VERSION "GT86 bus: what the GT86-ISF gateway sends (generated by tools/generate.py)"

NS_ :

BS_:

BU_: GATEWAY ADU GT86

BO_ 208 GT86_GSensor: 8 GATEWAY

BO_ 209 GT86_VehicleSpeed: 8 GATEWAY
 SG_ GT86_VehicleSpeed : 0|16@1+ (0.0565,0) [0|3702.73] "km/h" GT86

BO_ 210 GT86_Unknown_D2: 8 GATEWAY

BO_ 211 GT86_LightStatus: 8 GATEWAY

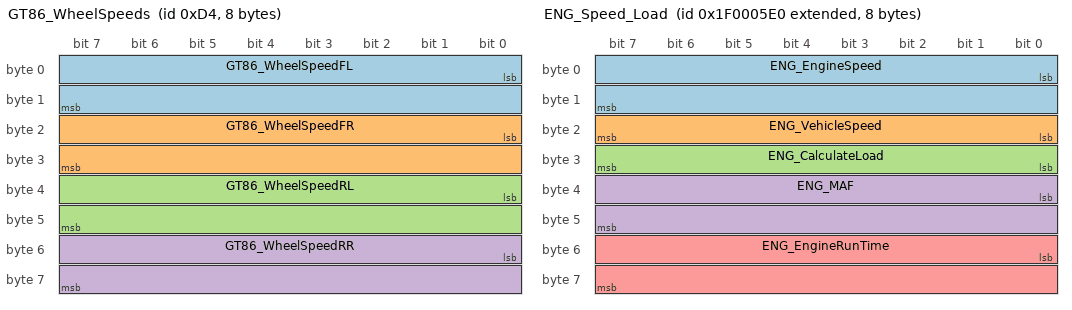
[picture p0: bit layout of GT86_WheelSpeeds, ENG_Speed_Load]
BO_ 212 GT86_WheelSpeeds: 8 GATEWAY
 SG_ GT86_WheelSpeedFL : 0|16@1+ (0.0565,0) [0|3702.73] "km/h" GT86
 SG_ GT86_WheelSpeedFR : 16|16@1+ (0.0565,0) [0|3702.73] "km/h" GT86
 SG_ GT86_WheelSpeedRL : 32|16@1+ (0.0565,0) [0|3702.73] "km/h" GT86
 SG_ GT86_WheelSpeedRR : 48|16@1+ (0.0565,0) [0|3702.73] "km/h" GT86

BO_ 320 GT86_EngineData1: 8 GATEWAY

BO_ 321 GT86_EngineData2: 8 GATEWAY
 SG_ GT86_EngineRPM : 32|14@1+ (1,0) [0|16383] "rpm" GT86

BO_ 322 GT86_EngineMisc: 8 GATEWAY

BO_ 324 GT86_BrakeData1: 8 GATEWAY

BO_ 864 GT86_Temperatures: 8 GATEWAY
 SG_ GT86_EngineOilTemperature : 16|8@1+ (1,-40) [-40|215] "°C" GT86
 SG_ GT86_CoolantTemperature : 24|8@1+ (1,-40) [-40|215] "°C" GT86

BO_ 865 GT86_GearData2: 8 GATEWAY

BO_ 880 GT86_SteeringTorque2: 8 GATEWAY

BO_ 1224 GT86_Unknown_4C8: 8 GATEWAY

BO_ 1953 GT86_ClusterDiagRequest: 8 GATEWAY

BO_ 1961 GT86_ClusterDiagResponse: 8 GATEWAY

BO_ 2667578848 ENG_Speed_Load: 8 GATEWAY
 SG_ ENG_EngineSpeed : 0|16@1+ (0.25,0) [0|16383.8] "rpm" ADU
 SG_ ENG_VehicleSpeed : 16|8@1+ (1,0) [0|255] "km/h" ADU
 SG_ ENG_CalculateLoad : 24|8@1+ (0.39215686274509803,0) [0|100] "%" ADU
 SG_ ENG_MAF : 32|16@1+ (0.01,0) [0|655.35] "g/s" ADU
 SG_ ENG_EngineRunTime : 48|16@1+ (1,0) [0|65535] "s" ADU

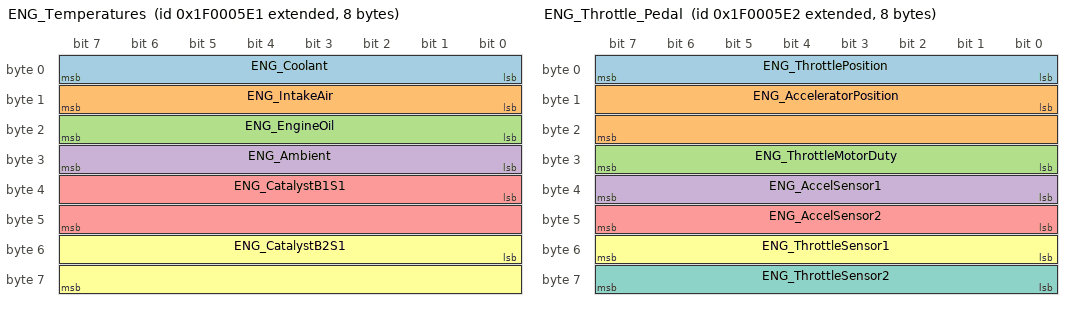
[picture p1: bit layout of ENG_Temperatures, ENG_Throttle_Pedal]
BO_ 2667578849 ENG_Temperatures: 8 GATEWAY
 SG_ ENG_Coolant : 0|8@1+ (1,-40) [-40|215] "°C" ADU
 SG_ ENG_IntakeAir : 8|8@1+ (1,-40) [-40|215] "°C" ADU
 SG_ ENG_EngineOil : 16|8@1+ (1,-40) [-40|215] "°C" ADU
 SG_ ENG_Ambient : 24|8@1+ (1,-40) [-40|215] "°C" ADU
 SG_ ENG_CatalystB1S1 : 32|16@1+ (0.1,-40) [-40|6513.5] "°C" ADU
 SG_ ENG_CatalystB2S1 : 48|16@1+ (0.1,-40) [-40|6513.5] "°C" ADU

BO_ 2667578850 ENG_Throttle_Pedal: 8 GATEWAY
 SG_ ENG_ThrottlePosition : 0|8@1+ (0.39215686274509803,0) [0|100] "%" ADU
 SG_ ENG_AcceleratorPosition : 8|16@1+ (0.006103515625,0) [0|399.994] "%" ADU
 SG_ ENG_ThrottleMotorDuty : 24|8@1+ (0.39215686274509803,0) [0|100] "%" ADU
 SG_ ENG_AccelSensor1 : 32|8@1+ (0.39215686274509803,0) [0|100] "%" ADU
 SG_ ENG_AccelSensor2 : 40|8@1+ (0.39215686274509803,0) [0|100] "%" ADU
 SG_ ENG_ThrottleSensor1 : 48|8@1+ (0.39215686274509803,0) [0|100] "%" ADU
 SG_ ENG_ThrottleSensor2 : 56|8@1+ (0.39215686274509803,0) [0|100] "%" ADU

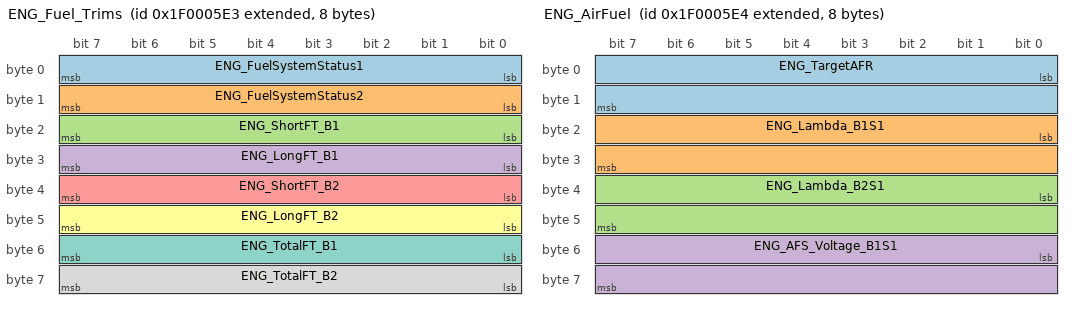
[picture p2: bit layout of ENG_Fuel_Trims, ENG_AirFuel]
BO_ 2667578851 ENG_Fuel_Trims: 8 GATEWAY
 SG_ ENG_FuelSystemStatus1 : 0|8@1+ (1,0) [0|255] "" ADU
 SG_ ENG_FuelSystemStatus2 : 8|8@1+ (1,0) [0|255] "" ADU
 SG_ ENG_ShortFT_B1 : 16|8@1+ (0.78125,-100) [-100|99.2188] "%" ADU
 SG_ ENG_LongFT_B1 : 24|8@1+ (0.78125,-100) [-100|99.2188] "%" ADU
 SG_ ENG_ShortFT_B2 : 32|8@1+ (0.78125,-100) [-100|99.2188] "%" ADU
 SG_ ENG_LongFT_B2 : 40|8@1+ (0.78125,-100) [-100|99.2188] "%" ADU
 SG_ ENG_TotalFT_B1 : 48|8@1+ (0.00390625,-0.5) [-0.5|0.496094] "" ADU
 SG_ ENG_TotalFT_B2 : 56|8@1+ (0.00390625,-0.5) [-0.5|0.496094] "" ADU

BO_ 2667578852 ENG_AirFuel: 8 GATEWAY
 SG_ ENG_TargetAFR : 0|16@1+ (3.05e-05,0) [0|1.99882] "" ADU
 SG_ ENG_Lambda_B1S1 : 16|16@1+ (3.05e-05,0) [0|1.99882] "" ADU
 SG_ ENG_Lambda_B2S1 : 32|16@1+ (3.05e-05,0) [0|1.99882] "" ADU
 SG_ ENG_AFS_Voltage_B1S1 : 48|16@1+ (0.000122,0) [0|7.99527] "V" ADU

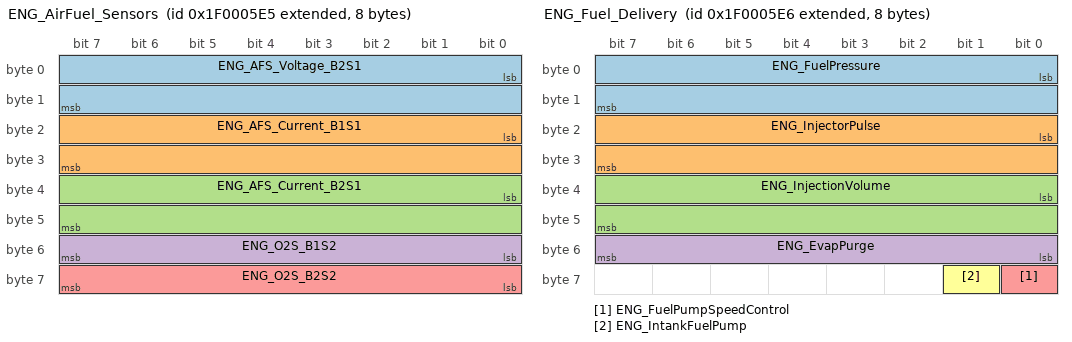
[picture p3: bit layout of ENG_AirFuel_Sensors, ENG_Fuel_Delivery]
BO_ 2667578853 ENG_AirFuel_Sensors: 8 GATEWAY
 SG_ ENG_AFS_Voltage_B2S1 : 0|16@1+ (0.000122,0) [0|7.99527] "V" ADU
 SG_ ENG_AFS_Current_B1S1 : 16|16@1+ (0.00390625,-128) [-128|127.996] "mA" ADU
 SG_ ENG_AFS_Current_B2S1 : 32|16@1+ (0.00390625,-128) [-128|127.996] "mA" ADU
 SG_ ENG_O2S_B1S2 : 48|8@1+ (0.005,0) [0|1.275] "V" ADU
 SG_ ENG_O2S_B2S2 : 56|8@1+ (0.005,0) [0|1.275] "V" ADU

BO_ 2667578854 ENG_Fuel_Delivery: 8 GATEWAY
 SG_ ENG_FuelPressure : 0|16@1+ (10,0) [0|655350] "kPa" ADU
 SG_ ENG_InjectorPulse : 16|16@1+ (1,0) [0|65535] "us" ADU
 SG_ ENG_InjectionVolume : 32|16@1+ (3.125e-05,0) [0|2.04797] "cm^3" ADU
 SG_ ENG_EvapPurge : 48|8@1+ (0.39215686274509803,0) [0|100] "%" ADU
 SG_ ENG_FuelPumpSpeedControl : 56|1@1+ (1,0) [0|1] "" ADU
 SG_ ENG_IntankFuelPump : 57|1@1+ (1,0) [0|1] "" ADU

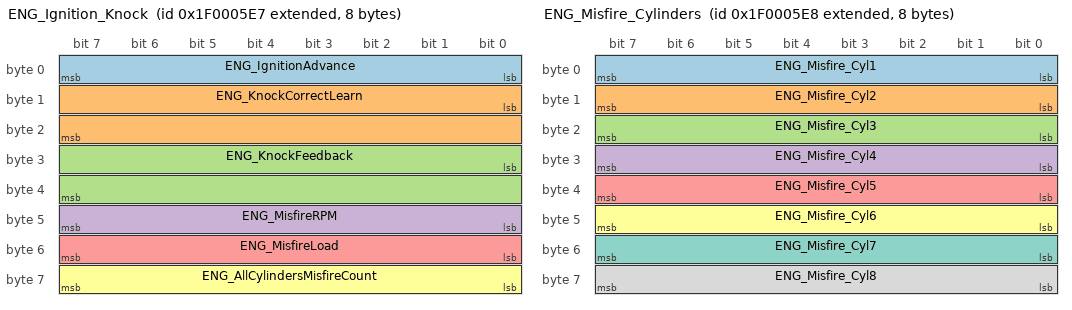
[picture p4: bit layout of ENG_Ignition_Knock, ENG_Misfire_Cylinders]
BO_ 2667578855 ENG_Ignition_Knock: 8 GATEWAY
 SG_ ENG_IgnitionAdvance : 0|8@1+ (0.5,-64) [-64|63.5] "°" ADU
 SG_ ENG_KnockCorrectLearn : 8|16@1+ (0.03125,-1024) [-1024|1023.97] "°" ADU
 SG_ ENG_KnockFeedback : 24|16@1+ (0.03125,-1024) [-1024|1023.97] "°" ADU
 SG_ ENG_MisfireRPM : 40|8@1+ (25,0) [0|6375] "rpm" ADU
 SG_ ENG_MisfireLoad : 48|8@1+ (0.015625,0) [0|3.98438] "" ADU
 SG_ ENG_AllCylindersMisfireCount : 56|8@1+ (1,0) [0|255] "" ADU

BO_ 2667578856 ENG_Misfire_Cylinders: 8 GATEWAY
 SG_ ENG_Misfire_Cyl1 : 0|8@1+ (1,0) [0|255] "" ADU
 SG_ ENG_Misfire_Cyl2 : 8|8@1+ (1,0) [0|255] "" ADU
 SG_ ENG_Misfire_Cyl3 : 16|8@1+ (1,0) [0|255] "" ADU
 SG_ ENG_Misfire_Cyl4 : 24|8@1+ (1,0) [0|255] "" ADU
 SG_ ENG_Misfire_Cyl5 : 32|8@1+ (1,0) [0|255] "" ADU
 SG_ ENG_Misfire_Cyl6 : 40|8@1+ (1,0) [0|255] "" ADU
 SG_ ENG_Misfire_Cyl7 : 48|8@1+ (1,0) [0|255] "" ADU
 SG_ ENG_Misfire_Cyl8 : 56|8@1+ (1,0) [0|255] "" ADU

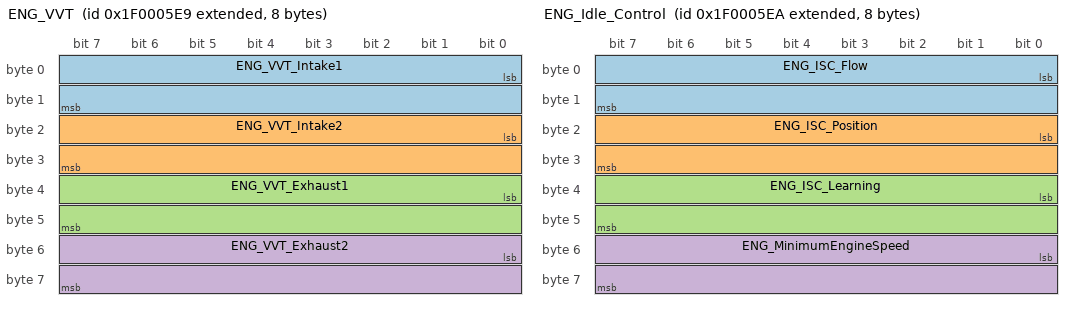
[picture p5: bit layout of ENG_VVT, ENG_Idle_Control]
BO_ 2667578857 ENG_VVT: 8 GATEWAY
 SG_ ENG_VVT_Intake1 : 0|16@1+ (0.009765625,0) [0|639.99] "°" ADU
 SG_ ENG_VVT_Intake2 : 16|16@1+ (0.009765625,0) [0|639.99] "°" ADU
 SG_ ENG_VVT_Exhaust1 : 32|16@1+ (0.009765625,0) [0|639.99] "°" ADU
 SG_ ENG_VVT_Exhaust2 : 48|16@1+ (0.009765625,0) [0|639.99] "°" ADU

BO_ 2667578858 ENG_Idle_Control: 8 GATEWAY
 SG_ ENG_ISC_Flow : 0|16@1+ (0.001220703125,0) [0|79.9988] "" ADU
 SG_ ENG_ISC_Position : 16|16@1+ (0.00762939453125,0) [0|499.992] "°" ADU
 SG_ ENG_ISC_Learning : 32|16@1+ (0.001220703125,-40) [-40|39.9988] "" ADU
 SG_ ENG_MinimumEngineSpeed : 48|16@1+ (0.78125,0) [0|51199.2] "rpm" ADU

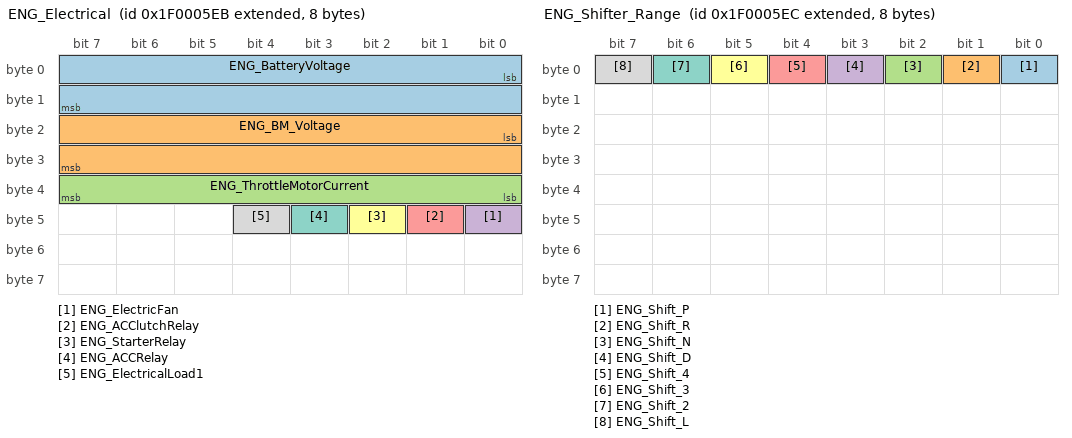
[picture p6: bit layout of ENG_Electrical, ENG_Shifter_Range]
BO_ 2667578859 ENG_Electrical: 8 GATEWAY
 SG_ ENG_BatteryVoltage : 0|16@1+ (0.001,0) [0|65.535] "V" ADU
 SG_ ENG_BM_Voltage : 16|16@1+ (0.001220703125,0) [0|79.9988] "V" ADU
 SG_ ENG_ThrottleMotorCurrent : 32|8@1+ (0.078125,0) [0|19.9219] "A" ADU
 SG_ ENG_ElectricFan : 40|1@1+ (1,0) [0|1] "" ADU
 SG_ ENG_ACClutchRelay : 41|1@1+ (1,0) [0|1] "" ADU
 SG_ ENG_StarterRelay : 42|1@1+ (1,0) [0|1] "" ADU
 SG_ ENG_ACCRelay : 43|1@1+ (1,0) [0|1] "" ADU
 SG_ ENG_ElectricalLoad1 : 44|1@1+ (1,0) [0|1] "" ADU

BO_ 2667578860 ENG_Shifter_Range: 8 GATEWAY
 SG_ ENG_Shift_P : 0|1@1+ (1,0) [0|1] "" ADU
 SG_ ENG_Shift_R : 1|1@1+ (1,0) [0|1] "" ADU
 SG_ ENG_Shift_N : 2|1@1+ (1,0) [0|1] "" ADU
 SG_ ENG_Shift_D : 3|1@1+ (1,0) [0|1] "" ADU
 SG_ ENG_Shift_4 : 4|1@1+ (1,0) [0|1] "" ADU
 SG_ ENG_Shift_3 : 5|1@1+ (1,0) [0|1] "" ADU
 SG_ ENG_Shift_2 : 6|1@1+ (1,0) [0|1] "" ADU
 SG_ ENG_Shift_L : 7|1@1+ (1,0) [0|1] "" ADU

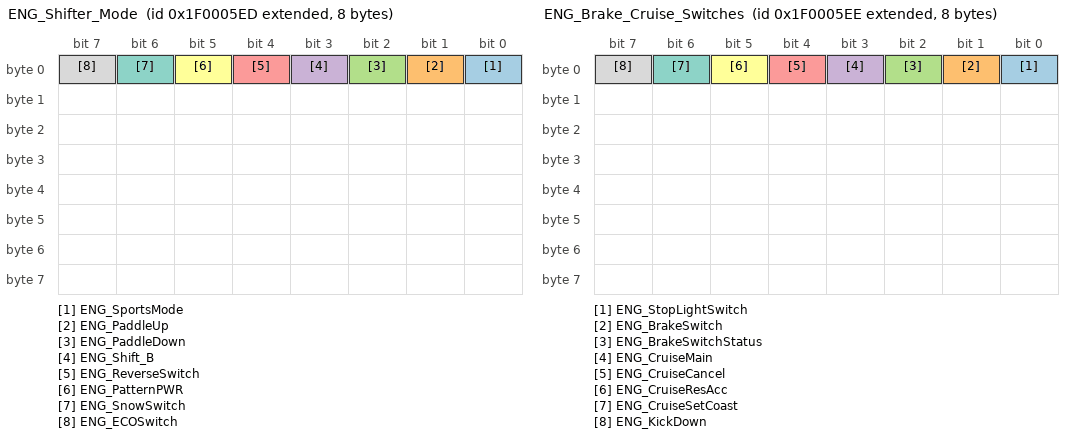
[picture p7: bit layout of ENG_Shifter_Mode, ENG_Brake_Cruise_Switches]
BO_ 2667578861 ENG_Shifter_Mode: 8 GATEWAY
 SG_ ENG_SportsMode : 0|1@1+ (1,0) [0|1] "" ADU
 SG_ ENG_PaddleUp : 1|1@1+ (1,0) [0|1] "" ADU
 SG_ ENG_PaddleDown : 2|1@1+ (1,0) [0|1] "" ADU
 SG_ ENG_Shift_B : 3|1@1+ (1,0) [0|1] "" ADU
 SG_ ENG_ReverseSwitch : 4|1@1+ (1,0) [0|1] "" ADU
 SG_ ENG_PatternPWR : 5|1@1+ (1,0) [0|1] "" ADU
 SG_ ENG_SnowSwitch : 6|1@1+ (1,0) [0|1] "" ADU
 SG_ ENG_ECOSwitch : 7|1@1+ (1,0) [0|1] "" ADU

BO_ 2667578862 ENG_Brake_Cruise_Switches: 8 GATEWAY
 SG_ ENG_StopLightSwitch : 0|1@1+ (1,0) [0|1] "" ADU
 SG_ ENG_BrakeSwitch : 1|1@1+ (1,0) [0|1] "" ADU
 SG_ ENG_BrakeSwitchStatus : 2|1@1+ (1,0) [0|1] "" ADU
 SG_ ENG_CruiseMain : 3|1@1+ (1,0) [0|1] "" ADU
 SG_ ENG_CruiseCancel : 4|1@1+ (1,0) [0|1] "" ADU
 SG_ ENG_CruiseResAcc : 5|1@1+ (1,0) [0|1] "" ADU
 SG_ ENG_CruiseSetCoast : 6|1@1+ (1,0) [0|1] "" ADU
 SG_ ENG_KickDown : 7|1@1+ (1,0) [0|1] "" ADU

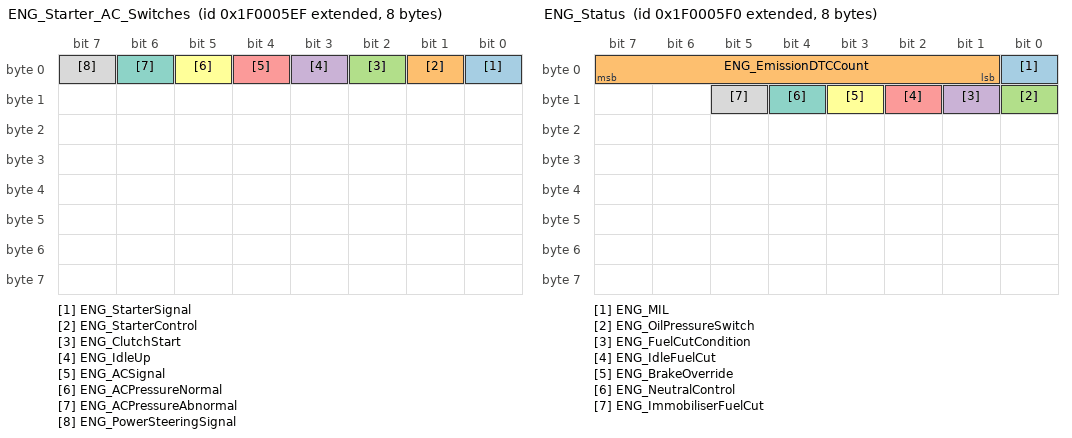
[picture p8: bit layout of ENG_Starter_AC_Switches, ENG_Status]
BO_ 2667578863 ENG_Starter_AC_Switches: 8 GATEWAY
 SG_ ENG_StarterSignal : 0|1@1+ (1,0) [0|1] "" ADU
 SG_ ENG_StarterControl : 1|1@1+ (1,0) [0|1] "" ADU
 SG_ ENG_ClutchStart : 2|1@1+ (1,0) [0|1] "" ADU
 SG_ ENG_IdleUp : 3|1@1+ (1,0) [0|1] "" ADU
 SG_ ENG_ACSignal : 4|1@1+ (1,0) [0|1] "" ADU
 SG_ ENG_ACPressureNormal : 5|1@1+ (1,0) [0|1] "" ADU
 SG_ ENG_ACPressureAbnormal : 6|1@1+ (1,0) [0|1] "" ADU
 SG_ ENG_PowerSteeringSignal : 7|1@1+ (1,0) [0|1] "" ADU

BO_ 2667578864 ENG_Status: 8 GATEWAY
 SG_ ENG_MIL : 0|1@1+ (1,0) [0|1] "" ADU
 SG_ ENG_EmissionDTCCount : 1|7@1+ (1,0) [0|127] "" ADU
 SG_ ENG_OilPressureSwitch : 8|1@1+ (1,0) [0|1] "" ADU
 SG_ ENG_FuelCutCondition : 9|1@1+ (1,0) [0|1] "" ADU
 SG_ ENG_IdleFuelCut : 10|1@1+ (1,0) [0|1] "" ADU
 SG_ ENG_BrakeOverride : 11|1@1+ (1,0) [0|1] "" ADU
 SG_ ENG_NeutralControl : 12|1@1+ (1,0) [0|1] "" ADU
 SG_ ENG_ImmobiliserFuelCut : 13|1@1+ (1,0) [0|1] "" ADU

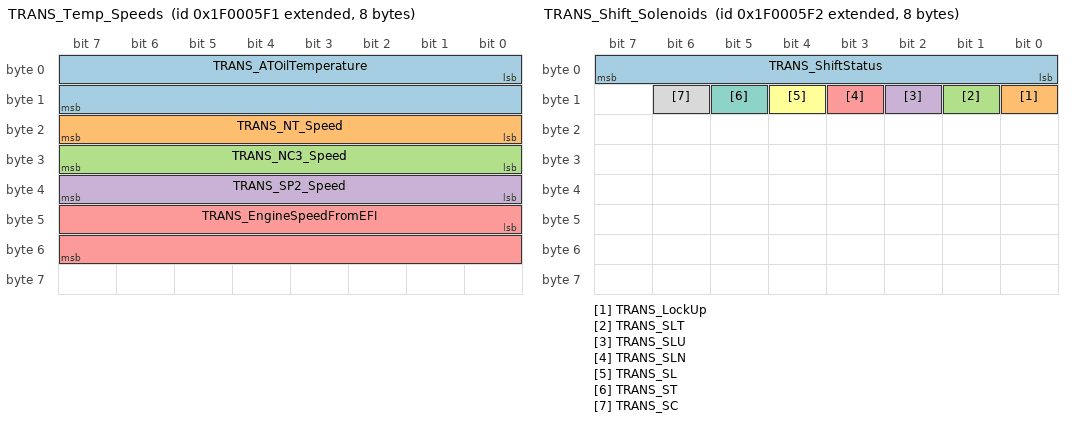
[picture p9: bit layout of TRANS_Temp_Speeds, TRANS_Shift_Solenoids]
BO_ 2667578865 TRANS_Temp_Speeds: 8 GATEWAY
 SG_ TRANS_ATOilTemperature : 0|16@1+ (0.00390625,-40) [-40|215.996] "°C" ADU
 SG_ TRANS_NT_Speed : 16|8@1+ (50,0) [0|12750] "rpm" ADU
 SG_ TRANS_NC3_Speed : 24|8@1+ (50,0) [0|12750] "rpm" ADU
 SG_ TRANS_SP2_Speed : 32|8@1+ (1,0) [0|255] "km/h" ADU
 SG_ TRANS_EngineSpeedFromEFI : 40|16@1+ (0.78125,0) [0|51199.2] "rpm" ADU

BO_ 2667578866 TRANS_Shift_Solenoids: 8 GATEWAY
 SG_ TRANS_ShiftStatus : 0|8@1+ (1,0) [0|255] "" ADU
 SG_ TRANS_LockUp : 8|1@1+ (1,0) [0|1] "" ADU
 SG_ TRANS_SLT : 9|1@1+ (1,0) [0|1] "" ADU
 SG_ TRANS_SLU : 10|1@1+ (1,0) [0|1] "" ADU
 SG_ TRANS_SLN : 11|1@1+ (1,0) [0|1] "" ADU
 SG_ TRANS_SL : 12|1@1+ (1,0) [0|1] "" ADU
 SG_ TRANS_ST : 13|1@1+ (1,0) [0|1] "" ADU
 SG_ TRANS_SC : 14|1@1+ (1,0) [0|1] "" ADU

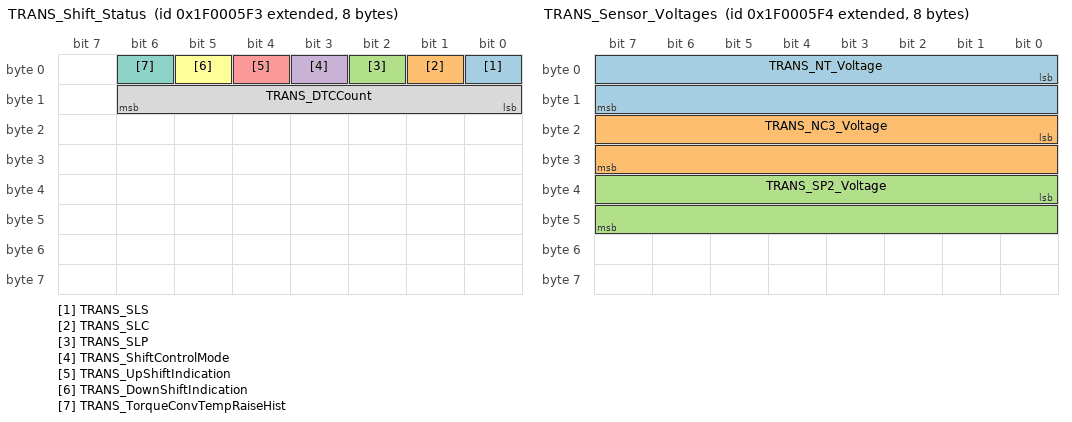
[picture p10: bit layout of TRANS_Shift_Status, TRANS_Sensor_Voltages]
BO_ 2667578867 TRANS_Shift_Status: 8 GATEWAY
 SG_ TRANS_SLS : 0|1@1+ (1,0) [0|1] "" ADU
 SG_ TRANS_SLC : 1|1@1+ (1,0) [0|1] "" ADU
 SG_ TRANS_SLP : 2|1@1+ (1,0) [0|1] "" ADU
 SG_ TRANS_ShiftControlMode : 3|1@1+ (1,0) [0|1] "" ADU
 SG_ TRANS_UpShiftIndication : 4|1@1+ (1,0) [0|1] "" ADU
 SG_ TRANS_DownShiftIndication : 5|1@1+ (1,0) [0|1] "" ADU
 SG_ TRANS_TorqueConvTempRaiseHist : 6|1@1+ (1,0) [0|1] "" ADU
 SG_ TRANS_DTCCount : 8|7@1+ (1,0) [0|127] "" ADU

BO_ 2667578868 TRANS_Sensor_Voltages: 8 GATEWAY
 SG_ TRANS_NT_Voltage : 0|16@1+ (7.62939453125e-05,0) [0|4.99992] "V" ADU
 SG_ TRANS_NC3_Voltage : 16|16@1+ (7.62939453125e-05,0) [0|4.99992] "V" ADU
 SG_ TRANS_SP2_Voltage : 32|16@1+ (7.62939453125e-05,0) [0|4.99992] "V" ADU

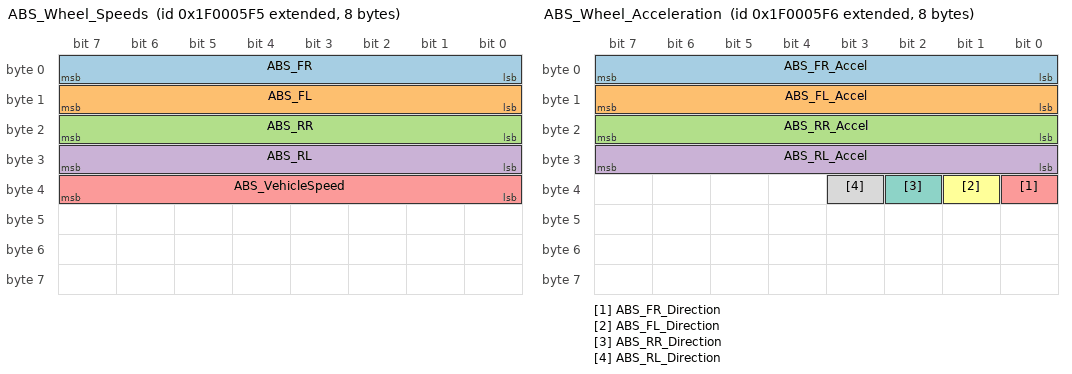
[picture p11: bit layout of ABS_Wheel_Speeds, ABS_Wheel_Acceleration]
BO_ 2667578869 ABS_Wheel_Speeds: 8 GATEWAY
 SG_ ABS_FR : 0|8@1+ (1.28,0) [0|326.4] "km/h" ADU
 SG_ ABS_FL : 8|8@1+ (1.28,0) [0|326.4] "km/h" ADU
 SG_ ABS_RR : 16|8@1+ (1.28,0) [0|326.4] "km/h" ADU
 SG_ ABS_RL : 24|8@1+ (1.28,0) [0|326.4] "km/h" ADU
 SG_ ABS_VehicleSpeed : 32|8@1+ (1.28,0) [0|326.4] "km/h" ADU

BO_ 2667578870 ABS_Wheel_Acceleration: 8 GATEWAY
 SG_ ABS_FR_Accel : 0|8@1- (0.16,0) [-20.48|20.32] "G" ADU
 SG_ ABS_FL_Accel : 8|8@1- (0.16,0) [-20.48|20.32] "G" ADU
 SG_ ABS_RR_Accel : 16|8@1- (0.16,0) [-20.48|20.32] "G" ADU
 SG_ ABS_RL_Accel : 24|8@1- (0.16,0) [-20.48|20.32] "G" ADU
 SG_ ABS_FR_Direction : 32|1@1+ (1,0) [0|1] "" ADU
 SG_ ABS_FL_Direction : 33|1@1+ (1,0) [0|1] "" ADU
 SG_ ABS_RR_Direction : 34|1@1+ (1,0) [0|1] "" ADU
 SG_ ABS_RL_Direction : 35|1@1+ (1,0) [0|1] "" ADU

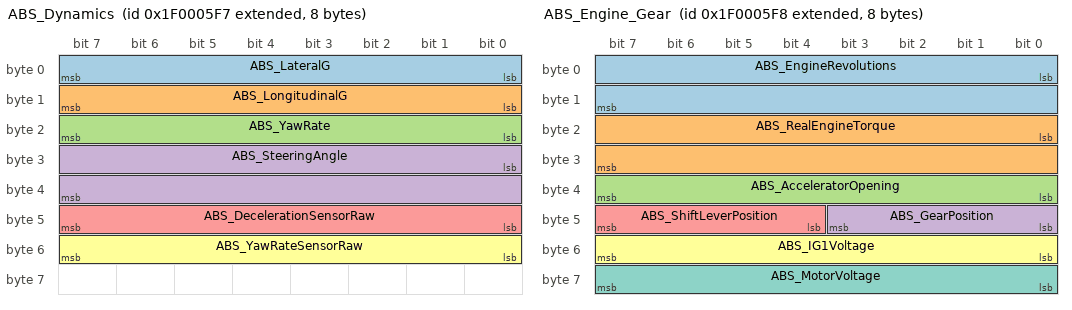
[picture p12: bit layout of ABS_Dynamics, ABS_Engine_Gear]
BO_ 2667578871 ABS_Dynamics: 8 GATEWAY
 SG_ ABS_LateralG : 0|8@1- (0.02,0) [-2.56|2.54] "G" ADU
 SG_ ABS_LongitudinalG : 8|8@1- (0.02,0) [-2.56|2.54] "G" ADU
 SG_ ABS_YawRate : 16|8@1+ (1,-128) [-128|127] "°/s" ADU
 SG_ ABS_SteeringAngle : 24|16@1+ (0.1,-3276.8) [-3276.8|3276.7] "°" ADU
 SG_ ABS_DecelerationSensorRaw : 40|8@1+ (0.014600296737417978,-1.8688339035246493) [-1.86883|1.85424] "G" ADU
 SG_ ABS_YawRateSensorRaw : 48|8@1+ (1,-128) [-128|127] "°/s" ADU

BO_ 2667578872 ABS_Engine_Gear: 8 GATEWAY
 SG_ ABS_EngineRevolutions : 0|16@1+ (1,0) [0|65535] "rpm" ADU
 SG_ ABS_RealEngineTorque : 16|16@1- (0.03125,0) [-1024|1023.97] "" ADU
 SG_ ABS_AcceleratorOpening : 32|8@1+ (0.5,0) [0|127.5] "%" ADU
 SG_ ABS_GearPosition : 40|4@1+ (1,0) [0|15] "" ADU
 SG_ ABS_ShiftLeverPosition : 44|4@1+ (1,0) [0|15] "" ADU
 SG_ ABS_IG1Voltage : 48|8@1+ (0.0784313725490196,0) [0|20] "V" ADU
 SG_ ABS_MotorVoltage : 56|8@1+ (0.0784313725490196,0) [0|20] "V" ADU

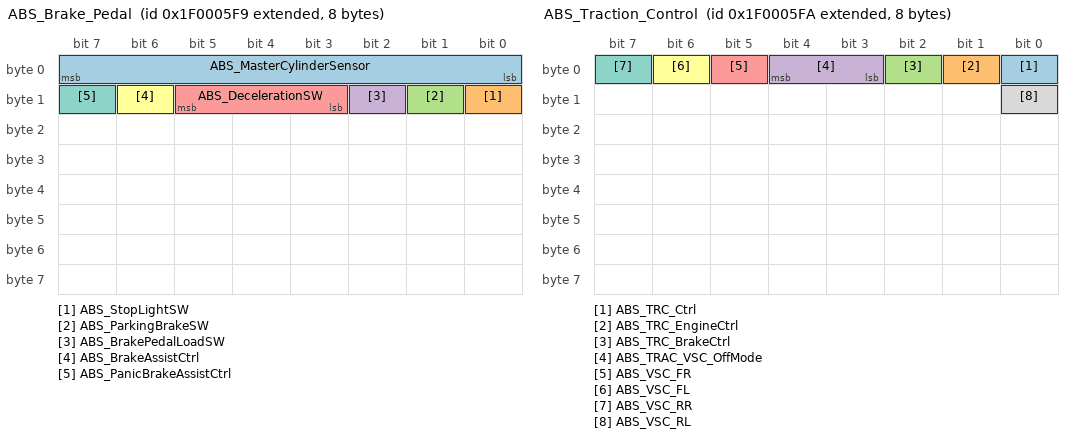
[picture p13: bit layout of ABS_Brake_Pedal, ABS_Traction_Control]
BO_ 2667578873 ABS_Brake_Pedal: 8 GATEWAY
 SG_ ABS_MasterCylinderSensor : 0|8@1+ (0.0196078431372549,0) [0|5] "V" ADU
 SG_ ABS_StopLightSW : 8|1@1+ (1,0) [0|1] "" ADU
 SG_ ABS_ParkingBrakeSW : 9|1@1+ (1,0) [0|1] "" ADU
 SG_ ABS_BrakePedalLoadSW : 10|1@1+ (1,0) [0|1] "" ADU
 SG_ ABS_DecelerationSW : 11|3@1+ (1,0) [0|7] "" ADU
 SG_ ABS_BrakeAssistCtrl : 14|1@1+ (1,0) [0|1] "" ADU
 SG_ ABS_PanicBrakeAssistCtrl : 15|1@1+ (1,0) [0|1] "" ADU

BO_ 2667578874 ABS_Traction_Control: 8 GATEWAY
 SG_ ABS_TRC_Ctrl : 0|1@1+ (1,0) [0|1] "" ADU
 SG_ ABS_TRC_EngineCtrl : 1|1@1+ (1,0) [0|1] "" ADU
 SG_ ABS_TRC_BrakeCtrl : 2|1@1+ (1,0) [0|1] "" ADU
 SG_ ABS_TRAC_VSC_OffMode : 3|2@1+ (1,0) [0|3] "" ADU
 SG_ ABS_VSC_FR : 5|1@1+ (1,0) [0|1] "" ADU
 SG_ ABS_VSC_FL : 6|1@1+ (1,0) [0|1] "" ADU
 SG_ ABS_VSC_RR : 7|1@1+ (1,0) [0|1] "" ADU
 SG_ ABS_VSC_RL : 8|1@1+ (1,0) [0|1] "" ADU

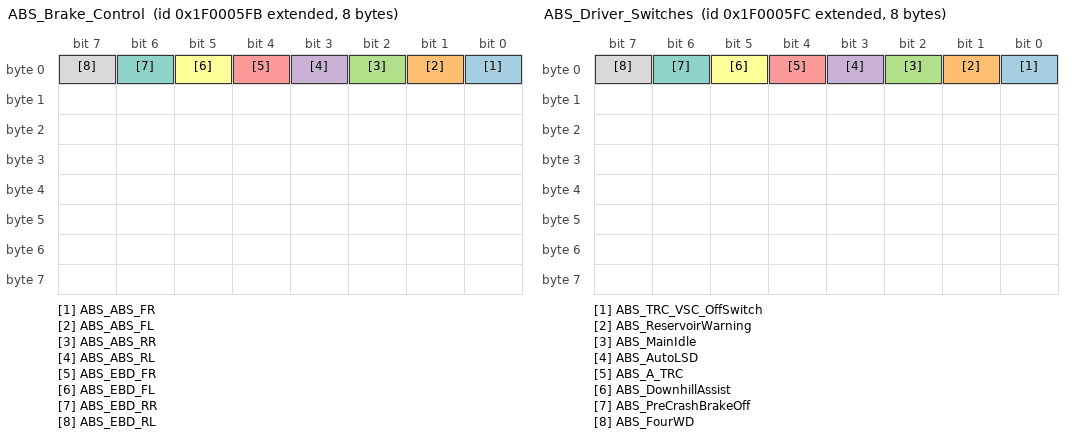
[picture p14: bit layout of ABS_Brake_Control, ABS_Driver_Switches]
BO_ 2667578875 ABS_Brake_Control: 8 GATEWAY
 SG_ ABS_ABS_FR : 0|1@1+ (1,0) [0|1] "" ADU
 SG_ ABS_ABS_FL : 1|1@1+ (1,0) [0|1] "" ADU
 SG_ ABS_ABS_RR : 2|1@1+ (1,0) [0|1] "" ADU
 SG_ ABS_ABS_RL : 3|1@1+ (1,0) [0|1] "" ADU
 SG_ ABS_EBD_FR : 4|1@1+ (1,0) [0|1] "" ADU
 SG_ ABS_EBD_FL : 5|1@1+ (1,0) [0|1] "" ADU
 SG_ ABS_EBD_RR : 6|1@1+ (1,0) [0|1] "" ADU
 SG_ ABS_EBD_RL : 7|1@1+ (1,0) [0|1] "" ADU

BO_ 2667578876 ABS_Driver_Switches: 8 GATEWAY
 SG_ ABS_TRC_VSC_OffSwitch : 0|1@1+ (1,0) [0|1] "" ADU
 SG_ ABS_ReservoirWarning : 1|1@1+ (1,0) [0|1] "" ADU
 SG_ ABS_MainIdle : 2|1@1+ (1,0) [0|1] "" ADU
 SG_ ABS_AutoLSD : 3|1@1+ (1,0) [0|1] "" ADU
 SG_ ABS_A_TRC : 4|1@1+ (1,0) [0|1] "" ADU
 SG_ ABS_DownhillAssist : 5|1@1+ (1,0) [0|1] "" ADU
 SG_ ABS_PreCrashBrakeOff : 6|1@1+ (1,0) [0|1] "" ADU
 SG_ ABS_FourWD : 7|1@1+ (1,0) [0|1] "" ADU

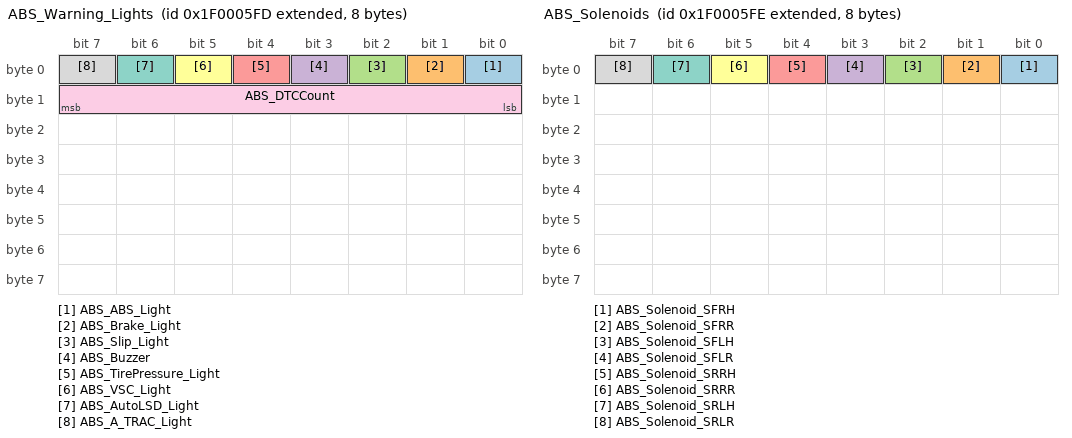
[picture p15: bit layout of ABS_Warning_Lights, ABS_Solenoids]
BO_ 2667578877 ABS_Warning_Lights: 8 GATEWAY
 SG_ ABS_ABS_Light : 0|1@1+ (1,0) [0|1] "" ADU
 SG_ ABS_Brake_Light : 1|1@1+ (1,0) [0|1] "" ADU
 SG_ ABS_Slip_Light : 2|1@1+ (1,0) [0|1] "" ADU
 SG_ ABS_Buzzer : 3|1@1+ (1,0) [0|1] "" ADU
 SG_ ABS_TirePressure_Light : 4|1@1+ (1,0) [0|1] "" ADU
 SG_ ABS_VSC_Light : 5|1@1+ (1,0) [0|1] "" ADU
 SG_ ABS_AutoLSD_Light : 6|1@1+ (1,0) [0|1] "" ADU
 SG_ ABS_A_TRAC_Light : 7|1@1+ (1,0) [0|1] "" ADU
 SG_ ABS_DTCCount : 8|8@1+ (1,0) [0|255] "" ADU

BO_ 2667578878 ABS_Solenoids: 8 GATEWAY
 SG_ ABS_Solenoid_SFRH : 0|1@1+ (1,0) [0|1] "" ADU
 SG_ ABS_Solenoid_SFRR : 1|1@1+ (1,0) [0|1] "" ADU
 SG_ ABS_Solenoid_SFLH : 2|1@1+ (1,0) [0|1] "" ADU
 SG_ ABS_Solenoid_SFLR : 3|1@1+ (1,0) [0|1] "" ADU
 SG_ ABS_Solenoid_SRRH : 4|1@1+ (1,0) [0|1] "" ADU
 SG_ ABS_Solenoid_SRRR : 5|1@1+ (1,0) [0|1] "" ADU
 SG_ ABS_Solenoid_SRLH : 6|1@1+ (1,0) [0|1] "" ADU
 SG_ ABS_Solenoid_SRLR : 7|1@1+ (1,0) [0|1] "" ADU

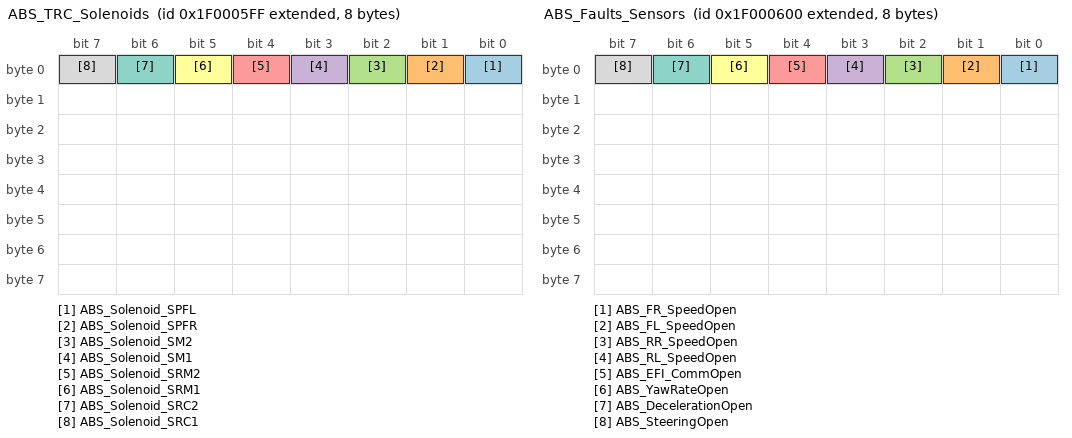
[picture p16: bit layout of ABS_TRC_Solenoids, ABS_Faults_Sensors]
BO_ 2667578879 ABS_TRC_Solenoids: 8 GATEWAY
 SG_ ABS_Solenoid_SPFL : 0|1@1+ (1,0) [0|1] "" ADU
 SG_ ABS_Solenoid_SPFR : 1|1@1+ (1,0) [0|1] "" ADU
 SG_ ABS_Solenoid_SM2 : 2|1@1+ (1,0) [0|1] "" ADU
 SG_ ABS_Solenoid_SM1 : 3|1@1+ (1,0) [0|1] "" ADU
 SG_ ABS_Solenoid_SRM2 : 4|1@1+ (1,0) [0|1] "" ADU
 SG_ ABS_Solenoid_SRM1 : 5|1@1+ (1,0) [0|1] "" ADU
 SG_ ABS_Solenoid_SRC2 : 6|1@1+ (1,0) [0|1] "" ADU
 SG_ ABS_Solenoid_SRC1 : 7|1@1+ (1,0) [0|1] "" ADU

BO_ 2667578880 ABS_Faults_Sensors: 8 GATEWAY
 SG_ ABS_FR_SpeedOpen : 0|1@1+ (1,0) [0|1] "" ADU
 SG_ ABS_FL_SpeedOpen : 1|1@1+ (1,0) [0|1] "" ADU
 SG_ ABS_RR_SpeedOpen : 2|1@1+ (1,0) [0|1] "" ADU
 SG_ ABS_RL_SpeedOpen : 3|1@1+ (1,0) [0|1] "" ADU
 SG_ ABS_EFI_CommOpen : 4|1@1+ (1,0) [0|1] "" ADU
 SG_ ABS_YawRateOpen : 5|1@1+ (1,0) [0|1] "" ADU
 SG_ ABS_DecelerationOpen : 6|1@1+ (1,0) [0|1] "" ADU
 SG_ ABS_SteeringOpen : 7|1@1+ (1,0) [0|1] "" ADU

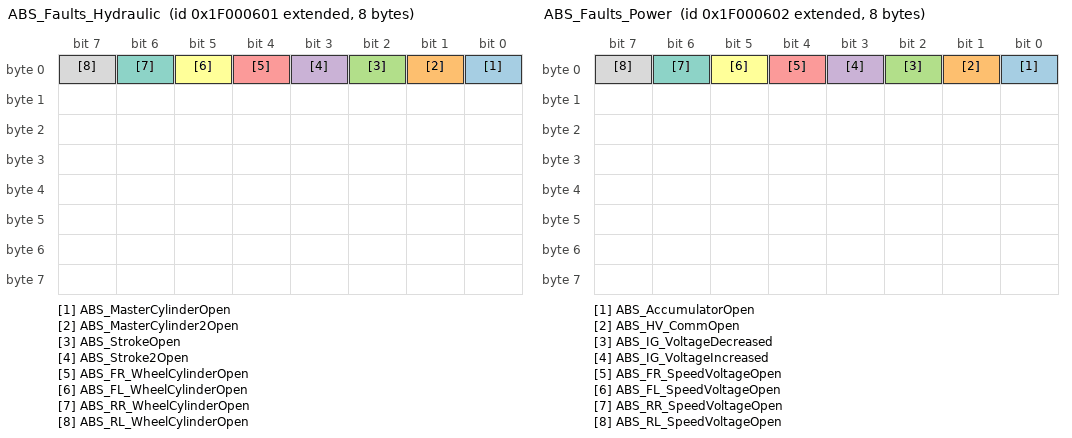
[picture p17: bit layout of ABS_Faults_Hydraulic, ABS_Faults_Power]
BO_ 2667578881 ABS_Faults_Hydraulic: 8 GATEWAY
 SG_ ABS_MasterCylinderOpen : 0|1@1+ (1,0) [0|1] "" ADU
 SG_ ABS_MasterCylinder2Open : 1|1@1+ (1,0) [0|1] "" ADU
 SG_ ABS_StrokeOpen : 2|1@1+ (1,0) [0|1] "" ADU
 SG_ ABS_Stroke2Open : 3|1@1+ (1,0) [0|1] "" ADU
 SG_ ABS_FR_WheelCylinderOpen : 4|1@1+ (1,0) [0|1] "" ADU
 SG_ ABS_FL_WheelCylinderOpen : 5|1@1+ (1,0) [0|1] "" ADU
 SG_ ABS_RR_WheelCylinderOpen : 6|1@1+ (1,0) [0|1] "" ADU
 SG_ ABS_RL_WheelCylinderOpen : 7|1@1+ (1,0) [0|1] "" ADU

BO_ 2667578882 ABS_Faults_Power: 8 GATEWAY
 SG_ ABS_AccumulatorOpen : 0|1@1+ (1,0) [0|1] "" ADU
 SG_ ABS_HV_CommOpen : 1|1@1+ (1,0) [0|1] "" ADU
 SG_ ABS_IG_VoltageDecreased : 2|1@1+ (1,0) [0|1] "" ADU
 SG_ ABS_IG_VoltageIncreased : 3|1@1+ (1,0) [0|1] "" ADU
 SG_ ABS_FR_SpeedVoltageOpen : 4|1@1+ (1,0) [0|1] "" ADU
 SG_ ABS_FL_SpeedVoltageOpen : 5|1@1+ (1,0) [0|1] "" ADU
 SG_ ABS_RR_SpeedVoltageOpen : 6|1@1+ (1,0) [0|1] "" ADU
 SG_ ABS_RL_SpeedVoltageOpen : 7|1@1+ (1,0) [0|1] "" ADU

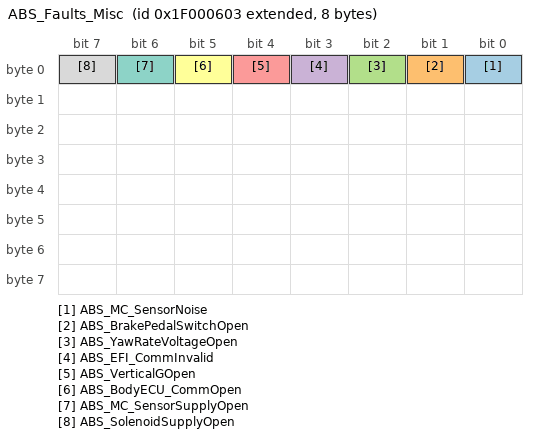
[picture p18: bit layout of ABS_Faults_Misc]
BO_ 2667578883 ABS_Faults_Misc: 8 GATEWAY
 SG_ ABS_MC_SensorNoise : 0|1@1+ (1,0) [0|1] "" ADU
 SG_ ABS_BrakePedalSwitchOpen : 1|1@1+ (1,0) [0|1] "" ADU
 SG_ ABS_YawRateVoltageOpen : 2|1@1+ (1,0) [0|1] "" ADU
 SG_ ABS_EFI_CommInvalid : 3|1@1+ (1,0) [0|1] "" ADU
 SG_ ABS_VerticalGOpen : 4|1@1+ (1,0) [0|1] "" ADU
 SG_ ABS_BodyECU_CommOpen : 5|1@1+ (1,0) [0|1] "" ADU
 SG_ ABS_MC_SensorSupplyOpen : 6|1@1+ (1,0) [0|1] "" ADU
 SG_ ABS_SolenoidSupplyOpen : 7|1@1+ (1,0) [0|1] "" ADU

CM_ BO_ 208 "Steering angle and lateral/longitudinal G; default bytes only: wheel straight, no G (the real car at rest sends 0E 00 01 00 00 00 00 FF)";
CM_ BO_ 209 "Vehicle speed (bytes 0-1, 0.0565 km/h per bit) and brake data; default is the real car at rest (00 00 13 00), foot off the brake";
CM_ BO_ 211 "VSC / TCS / SCS lights; default bytes only";
CM_ BO_ 212 "Four wheel speeds, 16 bits each, 0.0565 km/h per bit";
CM_ BO_ 320 "Default bytes only: bytes 2-3 did not move with engine speed in the drive capture";
CM_ BO_ 321 "Engine rpm in bits 32-45 (bytes 4-5, 14 bits, 1 rpm per bit); bits 46-47 kept from the default";
CM_ BO_ 324 "In the cluster capture but missing from the old Readme table";
CM_ BO_ 864 "Byte 2 engine oil temperature, byte 3 coolant temperature, both +40";
CM_ BO_ 2667578848 "From engine 21 01";
CM_ BO_ 2667578849 "From engine 21 01, engine 21 51, engine 21 05";
CM_ BO_ 2667578850 "From engine 21 01, engine 21 41";
CM_ BO_ 2667578851 "From engine 21 03, engine 21 3C";
CM_ BO_ 2667578852 "From engine 21 04";
CM_ BO_ 2667578853 "From engine 21 04";
CM_ BO_ 2667578854 "From engine 21 05, engine 21 3C, engine 21 03, engine 21 39";
CM_ BO_ 2667578855 "From engine 21 03, engine 21 37, engine 21 45";
CM_ BO_ 2667578856 "From engine 21 45";
CM_ BO_ 2667578857 "From engine 21 44";
CM_ BO_ 2667578858 "From engine 21 51, engine 21 52";
CM_ BO_ 2667578859 "From engine 21 01, engine 21 41, engine 21 39, engine 21 25";
CM_ BO_ 2667578860 "From engine 21 25";
CM_ BO_ 2667578861 "From engine 21 25";
CM_ BO_ 2667578862 "From engine 21 25, engine 21 21";
CM_ BO_ 2667578863 "From engine 21 25";
CM_ BO_ 2667578864 "From engine 21 06, engine 21 25, engine 21 37, engine 21 51";
CM_ BO_ 2667578865 "From ect 21 82, ect 21 81, ect 21 22";
CM_ BO_ 2667578866 "From ect 21 85";
CM_ BO_ 2667578867 "From ect 21 85, ect 21 83, ect 21 06";
CM_ BO_ 2667578868 "From ect 21 81";
CM_ BO_ 2667578869 "From abs 21 03, abs 21 21";
CM_ BO_ 2667578870 "From abs 21 42, abs 21 03";
CM_ BO_ 2667578871 "From abs 21 47, abs 21 05, abs 21 06";
CM_ BO_ 2667578872 "From abs 21 05, abs 21 1C, abs 21 0C";
CM_ BO_ 2667578873 "From abs 21 04, abs 21 1F, abs 21 5F";
CM_ BO_ 2667578874 "From abs 21 5A";
CM_ BO_ 2667578875 "From abs 21 5F";
CM_ BO_ 2667578876 "From abs 21 1D, abs 21 1F";
CM_ BO_ 2667578877 "From abs 21 3D, abs 21 E1";
CM_ BO_ 2667578878 "From abs 21 3F";
CM_ BO_ 2667578879 "From abs 21 3A";
CM_ BO_ 2667578880 "From abs 21 BE";
CM_ BO_ 2667578881 "From abs 21 BE";
CM_ BO_ 2667578882 "From abs 21 BE";
CM_ BO_ 2667578883 "From abs 21 BE";

VAL_ 2667578851 ENG_FuelSystemStatus1 0 "Unused" 1 "OL" 2 "CL" 4 "OLDrive" 8 "OLFault" 16 "CLFault" ;
VAL_ 2667578851 ENG_FuelSystemStatus2 0 "Unused" 1 "OL" 2 "CL" 4 "OLDrive" 8 "OLFault" 16 "CLFault" ;
VAL_ 2667578854 ENG_FuelPumpSpeedControl 0 "OFF" 1 "ON" ;
VAL_ 2667578854 ENG_IntankFuelPump 0 "OFF" 1 "ON" ;
VAL_ 2667578859 ENG_ElectricFan 0 "OFF" 1 "ON" ;
VAL_ 2667578859 ENG_ACClutchRelay 0 "OFF" 1 "ON" ;
VAL_ 2667578859 ENG_StarterRelay 0 "OFF" 1 "ON" ;
VAL_ 2667578859 ENG_ACCRelay 0 "OFF" 1 "ON" ;
VAL_ 2667578859 ENG_ElectricalLoad1 0 "OFF" 1 "ON" ;
VAL_ 2667578860 ENG_Shift_P 0 "OFF" 1 "ON" ;
VAL_ 2667578860 ENG_Shift_R 0 "OFF" 1 "ON" ;
VAL_ 2667578860 ENG_Shift_N 0 "OFF" 1 "ON" ;
VAL_ 2667578860 ENG_Shift_D 0 "OFF" 1 "ON" ;
VAL_ 2667578860 ENG_Shift_4 0 "OFF" 1 "ON" ;
VAL_ 2667578860 ENG_Shift_3 0 "OFF" 1 "ON" ;
VAL_ 2667578860 ENG_Shift_2 0 "OFF" 1 "ON" ;
VAL_ 2667578860 ENG_Shift_L 0 "OFF" 1 "ON" ;
VAL_ 2667578861 ENG_SportsMode 0 "OFF" 1 "ON" ;
VAL_ 2667578861 ENG_PaddleUp 0 "OFF" 1 "ON" ;
VAL_ 2667578861 ENG_PaddleDown 0 "OFF" 1 "ON" ;
VAL_ 2667578861 ENG_Shift_B 0 "OFF" 1 "ON" ;
VAL_ 2667578861 ENG_ReverseSwitch 0 "OFF" 1 "ON" ;
VAL_ 2667578861 ENG_PatternPWR 0 "OFF" 1 "ON" ;
VAL_ 2667578861 ENG_SnowSwitch 0 "OFF" 1 "ON" ;
VAL_ 2667578861 ENG_ECOSwitch 0 "OFF" 1 "ON" ;
VAL_ 2667578862 ENG_StopLightSwitch 0 "OFF" 1 "ON" ;
VAL_ 2667578862 ENG_BrakeSwitch 0 "OFF" 1 "ON" ;
VAL_ 2667578862 ENG_BrakeSwitchStatus 0 "Unable" 1 "Able" ;
VAL_ 2667578862 ENG_CruiseMain 0 "OFF" 1 "ON" ;
VAL_ 2667578862 ENG_CruiseCancel 0 "OFF" 1 "ON" ;
VAL_ 2667578862 ENG_CruiseResAcc 0 "OFF" 1 "ON" ;
VAL_ 2667578862 ENG_CruiseSetCoast 0 "OFF" 1 "ON" ;
VAL_ 2667578862 ENG_KickDown 0 "OFF" 1 "ON" ;
VAL_ 2667578863 ENG_StarterSignal 0 "OFF" 1 "ON" ;
VAL_ 2667578863 ENG_StarterControl 0 "OFF" 1 "ON" ;
VAL_ 2667578863 ENG_ClutchStart 0 "OFF" 1 "ON" ;
VAL_ 2667578863 ENG_IdleUp 0 "OFF" 1 "ON" ;
VAL_ 2667578863 ENG_ACSignal 0 "OFF" 1 "ON" ;
VAL_ 2667578863 ENG_ACPressureNormal 0 "OFF" 1 "ON" ;
VAL_ 2667578863 ENG_ACPressureAbnormal 0 "OFF" 1 "ON" ;
VAL_ 2667578863 ENG_PowerSteeringSignal 0 "OFF" 1 "ON" ;
VAL_ 2667578864 ENG_MIL 0 "OFF" 1 "ON" ;
VAL_ 2667578864 ENG_OilPressureSwitch 0 "OFF" 1 "ON" ;
VAL_ 2667578864 ENG_FuelCutCondition 0 "OFF" 1 "ON" ;
VAL_ 2667578864 ENG_IdleFuelCut 0 "OFF" 1 "ON" ;
VAL_ 2667578864 ENG_BrakeOverride 0 "OFF" 1 "ON" ;
VAL_ 2667578864 ENG_NeutralControl 0 "OFF" 1 "ON" ;
VAL_ 2667578864 ENG_ImmobiliserFuelCut 0 "OFF" 1 "ON" ;
VAL_ 2667578866 TRANS_ShiftStatus 1 "1st" 2 "2nd" 3 "3rd" 4 "4th" 5 "5th" 6 "6th" 7 "7th" 8 "8th" ;
VAL_ 2667578866 TRANS_LockUp 0 "OFF" 1 "ON" ;
VAL_ 2667578866 TRANS_SLT 0 "OFF" 1 "ON" ;
VAL_ 2667578866 TRANS_SLU 0 "OFF" 1 "ON" ;
VAL_ 2667578866 TRANS_SLN 0 "OFF" 1 "ON" ;
VAL_ 2667578866 TRANS_SL 0 "OFF" 1 "ON" ;
VAL_ 2667578866 TRANS_ST 0 "OFF" 1 "ON" ;
VAL_ 2667578866 TRANS_SC 0 "OFF" 1 "ON" ;
VAL_ 2667578867 TRANS_SLS 0 "OFF" 1 "ON" ;
VAL_ 2667578867 TRANS_SLC 0 "OFF" 1 "ON" ;
VAL_ 2667578867 TRANS_SLP 0 "OFF" 1 "ON" ;
VAL_ 2667578867 TRANS_ShiftControlMode 0 "S-mode" 1 "M-mode" ;
VAL_ 2667578867 TRANS_UpShiftIndication 0 "OFF" 1 "ON" ;
VAL_ 2667578867 TRANS_DownShiftIndication 0 "OFF" 1 "ON" ;
VAL_ 2667578867 TRANS_TorqueConvTempRaiseHist 0 "OFF" 1 "ON" ;
VAL_ 2667578870 ABS_FR_Direction 0 "Forward" 1 "Back" ;
VAL_ 2667578870 ABS_FL_Direction 0 "Forward" 1 "Back" ;
VAL_ 2667578870 ABS_RR_Direction 0 "Forward" 1 "Back" ;
VAL_ 2667578870 ABS_RL_Direction 0 "Forward" 1 "Back" ;
VAL_ 2667578872 ABS_GearPosition 0 "Fail" 1 "1st" 2 "2nd" 3 "3rd" 4 "4th" 5 "5th" 6 "6th" 7 "7th" 8 "'P" 9 "8th" 10 "9th" 11 "10th" 14 "R" 15 "Not R" ;
VAL_ 2667578872 ABS_ShiftLeverPosition 0 "Fail" 1 "1st" 2 "2nd" 3 "3rd" 4 "4th" 5 "5th" 6 "6th/B" 7 "D/M" 8 "'P" 14 "R" ;
VAL_ 2667578873 ABS_StopLightSW 0 "OFF" 1 "ON" ;
VAL_ 2667578873 ABS_ParkingBrakeSW 0 "OFF" 1 "ON" ;
VAL_ 2667578873 ABS_BrakePedalLoadSW 0 "OFF" 1 "ON" ;
VAL_ 2667578873 ABS_DecelerationSW 0 "Fail" 1 "Low" 2 "Mid" 4 "High" ;
VAL_ 2667578873 ABS_BrakeAssistCtrl 0 "OFF" 1 "ON" ;
VAL_ 2667578873 ABS_PanicBrakeAssistCtrl 0 "OFF" 1 "ON" ;
VAL_ 2667578874 ABS_TRC_Ctrl 0 "OFF" 1 "ON" ;
VAL_ 2667578874 ABS_TRC_EngineCtrl 0 "OFF" 1 "ON" ;
VAL_ 2667578874 ABS_TRC_BrakeCtrl 0 "OFF" 1 "ON" ;
VAL_ 2667578874 ABS_TRAC_VSC_OffMode 0 "Normal" 1 "TRC OFF" 2 "VSC Expert Mode" 3 "VSC OFF" ;
VAL_ 2667578874 ABS_VSC_FR 0 "OFF" 1 "ON" ;
VAL_ 2667578874 ABS_VSC_FL 0 "OFF" 1 "ON" ;
VAL_ 2667578874 ABS_VSC_RR 0 "OFF" 1 "ON" ;
VAL_ 2667578874 ABS_VSC_RL 0 "OFF" 1 "ON" ;
VAL_ 2667578875 ABS_ABS_FR 0 "OFF" 1 "ON" ;
VAL_ 2667578875 ABS_ABS_FL 0 "OFF" 1 "ON" ;
VAL_ 2667578875 ABS_ABS_RR 0 "OFF" 1 "ON" ;
VAL_ 2667578875 ABS_ABS_RL 0 "OFF" 1 "ON" ;
VAL_ 2667578875 ABS_EBD_FR 0 "OFF" 1 "ON" ;
VAL_ 2667578875 ABS_EBD_FL 0 "OFF" 1 "ON" ;
VAL_ 2667578875 ABS_EBD_RR 0 "OFF" 1 "ON" ;
VAL_ 2667578875 ABS_EBD_RL 0 "OFF" 1 "ON" ;
VAL_ 2667578876 ABS_TRC_VSC_OffSwitch 0 "OFF" 1 "ON" ;
VAL_ 2667578876 ABS_ReservoirWarning 0 "OFF" 1 "ON" ;
VAL_ 2667578876 ABS_MainIdle 0 "OFF" 1 "ON" ;
VAL_ 2667578876 ABS_AutoLSD 0 "OFF" 1 "ON" ;
VAL_ 2667578876 ABS_A_TRC 0 "OFF" 1 "ON" ;
VAL_ 2667578876 ABS_DownhillAssist 0 "OFF" 1 "ON" ;
VAL_ 2667578876 ABS_PreCrashBrakeOff 0 "OFF" 1 "ON" ;
VAL_ 2667578876 ABS_FourWD 0 "OFF" 1 "ON" ;
VAL_ 2667578877 ABS_ABS_Light 0 "OFF" 1 "ON" ;
VAL_ 2667578877 ABS_Brake_Light 0 "OFF" 1 "ON" ;
VAL_ 2667578877 ABS_Slip_Light 0 "OFF" 1 "ON" ;
VAL_ 2667578877 ABS_Buzzer 0 "OFF" 1 "ON" ;
VAL_ 2667578877 ABS_TirePressure_Light 0 "OFF" 1 "ON" ;
VAL_ 2667578877 ABS_VSC_Light 0 "OFF" 1 "ON" ;
VAL_ 2667578877 ABS_AutoLSD_Light 0 "OFF" 1 "ON" ;
VAL_ 2667578877 ABS_A_TRAC_Light 0 "OFF" 1 "ON" ;
VAL_ 2667578878 ABS_Solenoid_SFRH 0 "OFF" 1 "ON" ;
VAL_ 2667578878 ABS_Solenoid_SFRR 0 "OFF" 1 "ON" ;
VAL_ 2667578878 ABS_Solenoid_SFLH 0 "OFF" 1 "ON" ;
VAL_ 2667578878 ABS_Solenoid_SFLR 0 "OFF" 1 "ON" ;
VAL_ 2667578878 ABS_Solenoid_SRRH 0 "OFF" 1 "ON" ;
VAL_ 2667578878 ABS_Solenoid_SRRR 0 "OFF" 1 "ON" ;
VAL_ 2667578878 ABS_Solenoid_SRLH 0 "OFF" 1 "ON" ;
VAL_ 2667578878 ABS_Solenoid_SRLR 0 "OFF" 1 "ON" ;
VAL_ 2667578879 ABS_Solenoid_SPFL 0 "OFF" 1 "ON" ;
VAL_ 2667578879 ABS_Solenoid_SPFR 0 "OFF" 1 "ON" ;
VAL_ 2667578879 ABS_Solenoid_SM2 0 "OFF" 1 "ON" ;
VAL_ 2667578879 ABS_Solenoid_SM1 0 "OFF" 1 "ON" ;
VAL_ 2667578879 ABS_Solenoid_SRM2 0 "OFF" 1 "ON" ;
VAL_ 2667578879 ABS_Solenoid_SRM1 0 "OFF" 1 "ON" ;
VAL_ 2667578879 ABS_Solenoid_SRC2 0 "OFF" 1 "ON" ;
VAL_ 2667578879 ABS_Solenoid_SRC1 0 "OFF" 1 "ON" ;
VAL_ 2667578880 ABS_FR_SpeedOpen 0 "Normal" 1 "Error" ;
VAL_ 2667578880 ABS_FL_SpeedOpen 0 "Normal" 1 "Error" ;
VAL_ 2667578880 ABS_RR_SpeedOpen 0 "Normal" 1 "Error" ;
VAL_ 2667578880 ABS_RL_SpeedOpen 0 "Normal" 1 "Error" ;
VAL_ 2667578880 ABS_EFI_CommOpen 0 "Normal" 1 "Error" ;
VAL_ 2667578880 ABS_YawRateOpen 0 "Normal" 1 "Error" ;
VAL_ 2667578880 ABS_DecelerationOpen 0 "Normal" 1 "Error" ;
VAL_ 2667578880 ABS_SteeringOpen 0 "Normal" 1 "Error" ;
VAL_ 2667578881 ABS_MasterCylinderOpen 0 "Normal" 1 "Error" ;
VAL_ 2667578881 ABS_MasterCylinder2Open 0 "Normal" 1 "Error" ;
VAL_ 2667578881 ABS_StrokeOpen 0 "Normal" 1 "Error" ;
VAL_ 2667578881 ABS_Stroke2Open 0 "Normal" 1 "Error" ;
VAL_ 2667578881 ABS_FR_WheelCylinderOpen 0 "Normal" 1 "Error" ;
VAL_ 2667578881 ABS_FL_WheelCylinderOpen 0 "Normal" 1 "Error" ;
VAL_ 2667578881 ABS_RR_WheelCylinderOpen 0 "Normal" 1 "Error" ;
VAL_ 2667578881 ABS_RL_WheelCylinderOpen 0 "Normal" 1 "Error" ;
VAL_ 2667578882 ABS_AccumulatorOpen 0 "Normal" 1 "Error" ;
VAL_ 2667578882 ABS_HV_CommOpen 0 "Normal" 1 "Error" ;
VAL_ 2667578882 ABS_IG_VoltageDecreased 0 "Normal" 1 "Error" ;
VAL_ 2667578882 ABS_IG_VoltageIncreased 0 "Normal" 1 "Error" ;
VAL_ 2667578882 ABS_FR_SpeedVoltageOpen 0 "Normal" 1 "Error" ;
VAL_ 2667578882 ABS_FL_SpeedVoltageOpen 0 "Normal" 1 "Error" ;
VAL_ 2667578882 ABS_RR_SpeedVoltageOpen 0 "Normal" 1 "Error" ;
VAL_ 2667578882 ABS_RL_SpeedVoltageOpen 0 "Normal" 1 "Error" ;
VAL_ 2667578883 ABS_MC_SensorNoise 0 "Normal" 1 "Error" ;
VAL_ 2667578883 ABS_BrakePedalSwitchOpen 0 "Normal" 1 "Error" ;
VAL_ 2667578883 ABS_YawRateVoltageOpen 0 "Normal" 1 "Error" ;
VAL_ 2667578883 ABS_EFI_CommInvalid 0 "Normal" 1 "Error" ;
VAL_ 2667578883 ABS_VerticalGOpen 0 "Normal" 1 "Error" ;
VAL_ 2667578883 ABS_BodyECU_CommOpen 0 "Normal" 1 "Error" ;
VAL_ 2667578883 ABS_MC_SensorSupplyOpen 0 "Normal" 1 "Error" ;
VAL_ 2667578883 ABS_SolenoidSupplyOpen 0 "Normal" 1 "Error" ;
